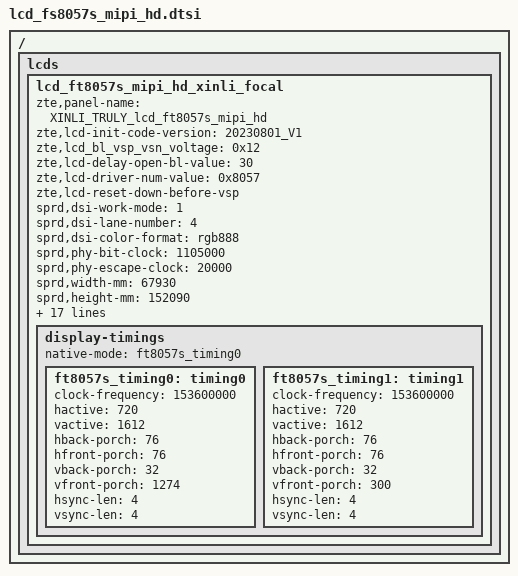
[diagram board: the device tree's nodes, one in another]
// SPDX-License-Identifier: GPL-2.0-only
/*
 * Unisoc ili9881c Truly LCD config DTS file
 *
 * Copyright (C) 2021, Unisoc Inc.
 */
/ {
	fragment {
		target-path = "/";
		__overlay__ {
			lcds {
				lcd_ft8057s_mipi_hd_xinli_focal: lcd_ft8057s_mipi_hd_xinli_focal {
					zte,panel-name = "XINLI_TRULY_lcd_ft8057s_mipi_hd";
					zte,lcd-init-code-version = "20230801_V1";
					zte,lcd_bl_vsp_vsn_voltage = <0x12>;
					zte,lcd-delay-open-bl-value = <30>;
					zte,lcd-driver-num-value = <0x8057>;
					zte,lcd-reset-down-before-vsp;

					sprd,dsi-work-mode = <1>;
					sprd,dsi-lane-number = <4>;
					sprd,dsi-color-format = "rgb888";

					sprd,phy-bit-clock = <1105000>;	/* kbps */
					sprd,phy-escape-clock = <20000>;/* kHz */

					sprd,width-mm = <67930>;/*zte mod for 6.56*/
					sprd,height-mm = <152090>;/*zte mod for 6.56*/
					lcd-glass = "TRULY";
					lcd-module = "XINLI";
					lcd-name = "FT8057S";

					sprd,esd-check-enable = <1>;
					sprd,esd-check-mode = <0>;
					sprd,esd-check-period = <1000>;
					sprd,esd-check-register = <0x0A>;
					sprd,esd-check-value = <0x9C>;
					sprd,vrr-enable;

					/*zte mod to 15ms*/
					sprd,reset-on-sequence = <1 15>, <0 10>, <1 50>;
					sprd,reset-off-sequence = <1 20>;

					//sprd,use-dcs-write;
					sprd,initial-command = [
						29 00 00 02 00 00
						29 00 00 04 FF 80 57 01
						29 00 00 02 00 80
						29 00 00 03 FF 80 57
						29 00 00 02 00 00
						29 00 00 05 2A 00 00 02 CF
						29 00 00 02 00 00
						29 00 00 05 2B 00 00 06 4B
						29 00 00 02 00 A3
						29 00 00 05 B3 06 4C 00 18
						29 00 00 02 00 93
						29 00 00 02 C5 61
						29 00 00 02 00 97
						29 00 00 02 C5 61
						29 00 00 02 00 9A
						29 00 00 02 C5 37
						29 00 00 02 00 9C
						29 00 00 02 C5 37
						29 00 00 02 00 B6
						29 00 00 03 C5 4D 4D
						29 00 00 02 00 B8
						29 00 00 03 C5 2D 2D
						29 00 00 02 00 00
						29 00 00 03 D8 35 35
						29 00 00 02 00 82
						29 00 00 02 C5 55
						29 00 00 02 00 83
						29 00 00 02 C5 07
						29 00 00 02 00 86
						29 00 00 02 f5 0d
						29 00 00 02 00 96
						29 00 00 02 f5 0d
						29 00 00 02 00 94
						29 00 00 02 C5 15
						29 00 00 02 00 9B
						29 00 00 02 C5 51
						29 00 00 02 00 A3
						29 00 00 02 A5 04
						29 00 00 02 00 99
						29 00 00 02 CF 56
						29 00 00 02 00 86
						29 00 00 02 B7 80
						29 00 00 02 00 A5
						29 00 00 02 B0 1D
						29 00 00 02 00 80
						29 00 00 07 C0 00 D2 00 2E 00 1C
						29 00 00 02 00 90
						29 00 00 07 C0 00 7F 00 2E 00 1C
						29 00 00 02 00 A0
						29 00 00 07 C0 00 D2 00 2E 00 1C
						29 00 00 02 00 B0
						29 00 00 06 C0 01 0F 00 2E 1C
						29 00 00 02 00 C1
						29 00 00 09 C0 01 33 01 0A 00 CD 01 8F
						29 00 00 02 00 70
						29 00 00 07 C0 00 7F 00 2E 00 1C
						29 00 00 02 00 A3
						29 00 00 07 C1 00 33 00 3C 00 02
						29 00 00 02 00 B7
						29 00 00 03 C1 00 33
						29 00 00 02 00 73
						29 00 00 03 CE 09 09
						29 00 00 02 00 80
						29 00 00 11 CE 01 81 09 09 00 78 00 96 00 78 00 96 00 78 00 96
						29 00 00 02 00 90
						29 00 00 10 CE 00 A5 16 8F 00 A5 80 09 09 00 07 D0 16 16 17
						29 00 00 02 00 A0
						29 00 00 04 CE 20 00 00
						29 00 00 02 00 B0
						29 00 00 04 CE 87 00 00
						29 00 00 02 00 D1
						29 00 00 08 CE 00 00 01 00 00 00 00
						29 00 00 02 00 E1
						29 00 00 0C CE 08 03 C3 03 C3 02 B0 00 00 00 00
						29 00 00 02 00 F1
						29 00 00 0A CE 14 14 1E 01 52 01 52 01 53
						29 00 00 02 00 B0
						29 00 00 05 CF 00 00 6D 71
						29 00 00 02 00 B5
						29 00 00 05 CF 03 03 5B 5F
						29 00 00 02 00 C0
						29 00 00 05 CF 06 06 47 4B
						29 00 00 02 00 C5
						29 00 00 05 CF 06 06 4B 4F
						29 00 00 02 00 60
						29 00 00 09 CF 00 00 6D 71 03 03 5B 5F
						29 00 00 02 00 70
						29 00 00 09 CF 00 00 65 69 03 03 53 57
						29 00 00 02 00 AA
						29 00 00 05 CF 80 80 1C 18
						29 00 00 02 00 D1
						29 00 00 0D C1 03 AA 05 22 09 59 05 87 08 23 0F AC
						29 00 00 02 00 E1
						29 00 00 03 C1 05 22
						29 00 00 02 00 E2
						29 00 00 0D CF 06 DE 06 DD 06 DD 06 DD 06 DD 06 DD
						29 00 00 02 00 80
						29 00 00 03 C1 00 00
						29 00 00 02 00 90
						29 00 00 02 C1 01
						29 00 00 02 00 F5
						29 00 00 02 CF 01
						29 00 00 02 00 F6
						29 00 00 02 CF 5A
						29 00 00 02 00 F1
						29 00 00 02 CF 5A
						29 00 00 02 00 F7
						29 00 00 02 CF 71
						29 00 00 02 00 D1
						29 00 00 08 CE 00 0A 01 01 00 F6 01
						29 00 00 02 00 E8
						29 00 00 05 CE 00 F6 00 F6
						29 00 00 02 00 80
						29 00 00 11 CC 00 00 17 01 03 05 21 1E 07 07 09 09 0B 0B 0D 0D
						29 00 00 02 00 90
						29 00 00 09 CC 0F 0F 11 11 00 00 00 00
						29 00 00 02 00 80
						29 00 00 11 CD 00 00 16 01 02 04 20 1E 06 06 08 08 0A 0A 0C 0C
						29 00 00 02 00 90
						29 00 00 09 CD 0E 0E 10 10 00 00 00 00
						29 00 00 02 00 80
						29 00 00 11 CB C1 C1 C1 C1 C1 C1 C1 C1 C1 C1 C1 C1 CF C1 C1 C1
						29 00 00 02 00 ED
						29 00 00 02 CB C1
						29 00 00 02 00 90
						29 00 00 11 CB 00 00 00 00 00 00 00 00 00 00 00 00 FC 00 00 00
						29 00 00 02 00 EE
						29 00 00 02 CB 00
						29 00 00 02 00 90
						29 00 00 02 C3 00
						29 00 00 02 00 A0
						29 00 00 09 CB 00 00 00 00 00 00 00 00
						29 00 00 02 00 B0
						29 00 00 05 CB 55 55 55 D5
						29 00 00 02 00 C0
						29 00 00 05 CB 55 55 55 D5
						29 00 00 02 00 D2
						29 00 00 0C CB 83 00 83 83 00 83 83 00 83 83 00
						29 00 00 02 00 E0
						29 00 00 0E CB 83 83 00 83 83 00 83 83 00 83 83 00 83
						29 00 00 02 00 FA
						29 00 00 03 CB 83 00
						29 00 00 02 00 EF
						29 00 00 02 CB 00
						29 00 00 02 00 68
						29 00 00 05 C2 8D 05 00 00
						29 00 00 02 00 6C
						29 00 00 05 C2 8C 05 00 00
						29 00 00 02 00 70
						29 00 00 05 C2 8B 05 00 00
						29 00 00 02 00 74
						29 00 00 05 C2 8A 05 00 00
						29 00 00 02 00 E0
						29 00 00 05 C3 00 00 00 00
						29 00 00 02 00 E4
						29 00 00 05 C3 00 00 00 00
						29 00 00 02 00 FE
						29 00 00 02 CB A0
						29 00 00 02 00 F5
						29 00 00 04 CD 89 55 88
						29 00 00 02 00 78
						29 00 00 05 C2 06 05 00 00
						29 00 00 02 00 7C
						29 00 00 05 C2 07 05 00 00
						29 00 00 02 00 EA
						29 00 00 09 C2 12 00 0E 0E 00 00 00 00
						29 00 00 02 00 8C
						29 00 00 06 C2 8A 04 05 7E 97
						29 00 00 02 00 91
						29 00 00 06 C2 89 05 05 7E 97
						29 00 00 02 00 96
						29 00 00 06 C2 88 06 05 7E 97
						29 00 00 02 00 9B
						29 00 00 06 C2 87 07 05 7E 97
						29 00 00 02 00 A0
						29 00 00 06 C2 86 00 05 7E 97
						29 00 00 02 00 A5
						29 00 00 06 C2 85 00 05 7E 97
						29 00 00 02 00 AA
						29 00 00 06 C2 84 00 05 7E 97
						29 00 00 02 00 AF
						29 00 00 06 C2 83 00 05 7E 97
						29 00 00 02 00 B4
						29 00 00 06 C2 82 01 05 7E 97
						29 00 00 02 00 B9
						29 00 00 06 C2 81 02 05 7E 97
						29 00 00 02 00 BE
						29 00 00 06 C2 80 03 05 7E 97
						29 00 00 02 00 C3
						29 00 00 06 C2 01 04 05 7E 97
						29 00 00 02 00 dc
						29 00 00 09 C2 bb bb bb bb bb bb 00 00
						29 00 00 02 00 98
						29 00 00 02 C4 08
						29 00 00 02 00 91
						29 00 00 05 E9 FF FF FF 00
						29 00 00 02 00 85
						29 00 00 02 C4 80
						29 00 00 02 00 81
						29 00 00 02 A4 73
						29 00 00 02 00 86
						29 00 00 02 A4 B6
						29 00 00 02 00 95
						29 00 00 02 C4 80
						29 00 00 02 00 CA
						29 00 00 03 C0 90 11
						29 00 00 02 00 B7
						29 00 00 02 F5 1D
						29 00 00 02 00 90
						29 00 00 02 C3 00
						29 00 00 02 00 B0
						29 00 00 02 C5 00
						29 00 00 02 00 B3
						29 00 00 02 C5 00
						29 00 00 02 00 B2
						29 00 00 02 C5 0D
						29 00 00 02 00 B5
						29 00 00 02 C5 02
						29 00 00 02 00 C2
						29 00 00 02 F5 42
						29 00 00 02 00 80
						29 00 00 02 CE 00
						29 00 00 02 00 D0
						29 00 00 02 CE 01
						29 00 00 02 00 E0
						29 00 00 02 CE 00
						29 00 00 02 00 A1
						29 00 00 02 C1 CC
						29 00 00 02 00 A6
						29 00 00 02 C1 10
						29 00 00 02 00 71
						29 00 00 06 C0 85 01 2B 00 22
						29 00 00 02 00 AE
						29 00 00 02 C1 80
						29 00 00 02 00 00
						29 00 00 02 00 BC
						29 00 00 03 C5 01 01
						29 00 00 04 FF 00 00 00
						29 00 00 02 00 80
						29 00 00 03 FF 00 00
						29 00 00 02 51 FF
						29 00 00 02 53 2C
						29 00 00 02 55 00
						05 78 00 01 11
						05 32 00 01 29
						];
					sprd,sleep-in-command = [
						05 32 00 01 28
						05 78 00 01 10
						29 00 00 02 00 00
						29 01 00 05 F7 5A A5 95 27
						];
					sprd,sleep-out-command = [
						05 78 00 01 11
						05 32 00 01 29
						];

					display-timings {
						native-mode = <&ft8057s_timing0>;

						ft8057s_timing0:timing0 {
							clock-frequency = <153600000>;
							hactive = <720>;
							vactive = <1612>;
							hback-porch = <76>;
							hfront-porch = <76>;
							vback-porch = <32>;
							vfront-porch = <1274>;
							hsync-len = <4>;
							vsync-len = <4>;
						};
						ft8057s_timing1:timing1 {
							clock-frequency = <153600000>;
							hactive = <720>;
							vactive = <1612>;
							hback-porch = <76>;
							hfront-porch = <76>;
							vback-porch = <32>;
							vfront-porch = <300>;
							hsync-len = <4>;
							vsync-len = <4>;
						};
					};
				};
			};
		};
	};
};
